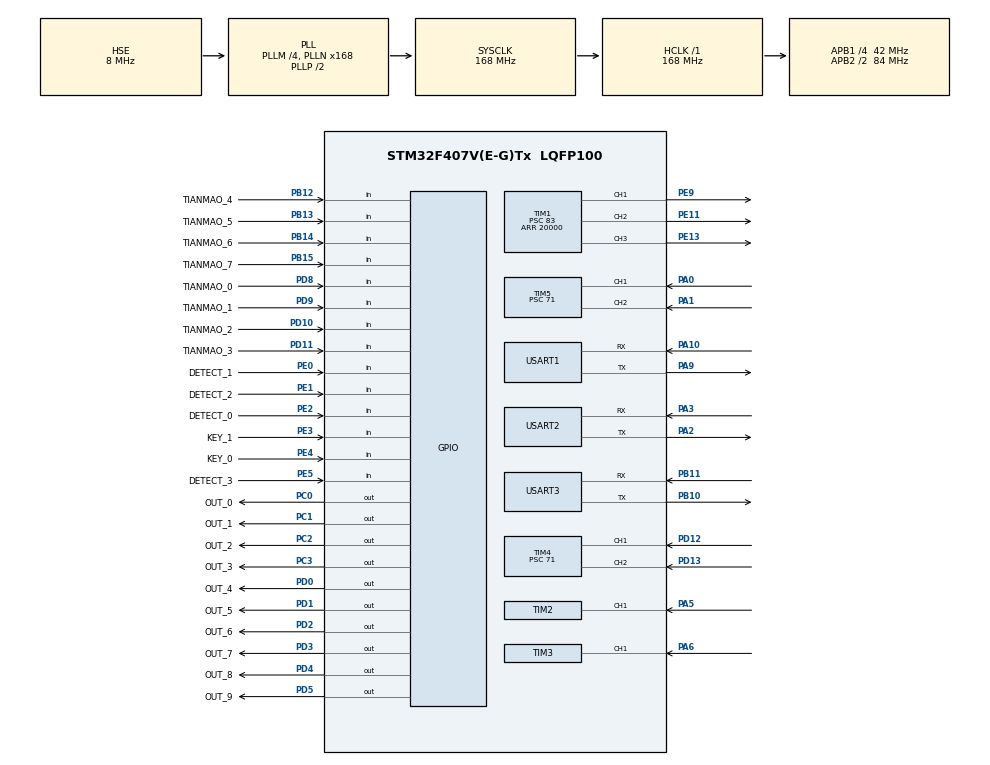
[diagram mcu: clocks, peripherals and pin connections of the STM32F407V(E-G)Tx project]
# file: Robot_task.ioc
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FREERTOS.INCLUDE_eTaskGetState=1
FREERTOS.INCLUDE_pcTaskGetTaskName=1
FREERTOS.INCLUDE_uxTaskGetStackHighWaterMark=1
FREERTOS.INCLUDE_uxTaskGetStackHighWaterMark2=1
FREERTOS.INCLUDE_vTaskCleanUpResources=1
FREERTOS.INCLUDE_vTaskDelayUntil=1
FREERTOS.INCLUDE_xQueueGetMutexHolder=1
FREERTOS.INCLUDE_xSemaphoreGetMutexHolder=1
FREERTOS.INCLUDE_xTaskAbortDelay=1
FREERTOS.INCLUDE_xTaskGetCurrentTaskHandle=1
FREERTOS.INCLUDE_xTaskGetHandle=1
FREERTOS.Tasks01=main_control,2,128,main_control_Task,Default,NULL,Dynamic,NULL,NULL;detect,1,128,detect_Task,Default,NULL,Dynamic,NULL,NULL;io_judge,0,128,io_Task,Default,NULL,Dynamic,NULL,NULL;wave_detect,0,128,wave_Task,Default,NULL,Dynamic,NULL,NULL;encoder,1,128,encoder_Task,Default,NULL,Dynamic,NULL,NULL
Mcu.Family=STM32F4
Mcu.Name=STM32F407V(E-G)Tx
Mcu.Package=LQFP100
NVIC.PriorityGroup=NVIC_PRIORITYGROUP_4
NVIC.TIM2_IRQn=true\:5\:0\:true\:false\:true\:true\:true\:true
NVIC.TIM3_IRQn=true\:5\:0\:true\:false\:true\:true\:true\:true
NVIC.TIM4_IRQn=true\:5\:0\:false\:false\:true\:true\:true\:true
NVIC.TIM5_IRQn=true\:5\:0\:false\:false\:true\:true\:true\:true
NVIC.USART1_IRQn=true\:5\:0\:false\:false\:true\:true\:true\:true
NVIC.USART2_IRQn=true\:5\:0\:false\:false\:true\:true\:true\:true
NVIC.USART3_IRQn=true\:5\:0\:false\:false\:true\:true\:true\:true
PA0-WKUP.Signal=S_TIM5_CH1
PA1.Signal=S_TIM5_CH2
PA10.Mode=Asynchronous
PA10.Signal=USART1_RX
PA2.Mode=Asynchronous
PA2.Signal=USART2_TX
PA3.Mode=Asynchronous
PA3.Signal=USART2_RX
PA5.Signal=S_TIM2_CH1_ETR
PA6.Signal=S_TIM3_CH1
PA9.Mode=Asynchronous
PA9.Signal=USART1_TX
PB10.Mode=Asynchronous
PB10.Signal=USART3_TX
PB11.Mode=Asynchronous
PB11.Signal=USART3_RX
PB12.GPIO_Label=TIANMAO_4
PB12.Signal=GPIO_Input
PB13.GPIO_Label=TIANMAO_5
PB13.Signal=GPIO_Input
PB14.GPIO_Label=TIANMAO_6
PB14.Signal=GPIO_Input
PB15.GPIO_Label=TIANMAO_7
PB15.Signal=GPIO_Input
PC0.GPIO_Label=OUT_0
PC0.Signal=GPIO_Output
PC1.GPIO_Label=OUT_1
PC1.Signal=GPIO_Output
PC2.GPIO_Label=OUT_2
PC2.Signal=GPIO_Output
PC3.GPIO_Label=OUT_3
PC3.Signal=GPIO_Output
PD0.GPIO_Label=OUT_4
PD0.Signal=GPIO_Output
PD1.GPIO_Label=OUT_5
PD1.Signal=GPIO_Output
PD10.GPIO_Label=TIANMAO_2
PD10.Signal=GPIO_Input
PD11.GPIO_Label=TIANMAO_3
PD11.Signal=GPIO_Input
PD12.Signal=S_TIM4_CH1
PD13.Signal=S_TIM4_CH2
PD2.GPIO_Label=OUT_6
PD2.Signal=GPIO_Output
PD3.GPIO_Label=OUT_7
PD3.Signal=GPIO_Output
PD4.GPIO_Label=OUT_8
PD4.Signal=GPIO_Output
PD5.GPIO_Label=OUT_9
PD5.Signal=GPIO_Output
PD8.GPIO_Label=TIANMAO_0
PD8.Signal=GPIO_Input
PD9.GPIO_Label=TIANMAO_1
PD9.Signal=GPIO_Input
PE0.GPIO_Label=DETECT_1
PE0.Signal=GPIO_Input
PE1.GPIO_Label=DETECT_2
PE1.Signal=GPIO_Input
PE11.Signal=S_TIM1_CH2
PE13.Signal=S_TIM1_CH3
PE2.GPIO_Label=DETECT_0
PE2.Signal=GPIO_Input
PE3.GPIO_Label=KEY_1
PE3.GPIO_PuPd=GPIO_PULLUP
PE3.Signal=GPIO_Input
PE4.GPIO_Label=KEY_0
PE4.GPIO_PuPd=GPIO_PULLUP
PE4.Signal=GPIO_Input
PE5.GPIO_Label=DETECT_3
PE5.Signal=GPIO_Input
PE9.Signal=S_TIM1_CH1
PH0-OSC_IN.Mode=HSE-External-Oscillator
PH0-OSC_IN.Signal=RCC_OSC_IN
PH1-OSC_OUT.Mode=HSE-External-Oscillator
PH1-OSC_OUT.Signal=RCC_OSC_OUT
ProjectManager.HeapSize=0x200
ProjectManager.StackSize=0x400
ProjectManager.TargetToolchain=MDK-ARM V5
RCC.48MHZClocksFreq_Value=84000000
RCC.AHBFreq_Value=168000000
RCC.APB1CLKDivider=RCC_HCLK_DIV4
RCC.APB1Freq_Value=42000000
RCC.APB1TimFreq_Value=84000000
RCC.APB2CLKDivider=RCC_HCLK_DIV2
RCC.APB2Freq_Value=84000000
RCC.APB2TimFreq_Value=168000000
RCC.CortexFreq_Value=168000000
RCC.HCLKFreq_Value=168000000
RCC.HSE_VALUE=8000000
RCC.HSI_VALUE=16000000
RCC.LSE_VALUE=32768
RCC.PLLM=4
RCC.PLLN=168
RCC.PLLSourceVirtual=RCC_PLLSOURCE_HSE
RCC.SYSCLKFreq_VALUE=168000000
RCC.SYSCLKSource=RCC_SYSCLKSOURCE_PLLCLK
RCC.VCOOutputFreq_Value=336000000
SH.S_TIM1_CH1.0=TIM1_CH1,PWM Generation1 CH1
SH.S_TIM1_CH2.0=TIM1_CH2,PWM Generation2 CH2
SH.S_TIM1_CH3.0=TIM1_CH3,PWM Generation3 CH3
SH.S_TIM2_CH1_ETR.0=TIM2_CH1,Input_Capture1_from_TI1
SH.S_TIM3_CH1.0=TIM3_CH1,Input_Capture1_from_TI1
SH.S_TIM4_CH1.0=TIM4_CH1,Encoder_Interface
SH.S_TIM4_CH2.0=TIM4_CH2,Encoder_Interface
SH.S_TIM5_CH1.0=TIM5_CH1,Encoder_Interface
SH.S_TIM5_CH2.0=TIM5_CH2,Encoder_Interface
TIM1.Channel-PWM\ Generation1\ CH1=TIM_CHANNEL_1
TIM1.Channel-PWM\ Generation2\ CH2=TIM_CHANNEL_2
TIM1.Channel-PWM\ Generation3\ CH3=TIM_CHANNEL_3
TIM1.Period=20000
TIM1.Prescaler=83
TIM2.Channel-Input_Capture1_from_TI1=TIM_CHANNEL_1
TIM2.Period=65535
TIM2.Prescaler=71
TIM3.Channel-Input_Capture1_from_TI1=TIM_CHANNEL_1
TIM3.Prescaler=7199
TIM4.Prescaler=71
TIM5.Period=65535
TIM5.Prescaler=71
TIM6.Prescaler=71
USART1.VirtualMode=VM_ASYNC
USART2.VirtualMode=VM_ASYNC
USART3.VirtualMode=VM_ASYNC
VP_FREERTOS_VS_CMSIS_V1.Mode=CMSIS_V1
VP_TIM6_VS_ClockSourceINT.Mode=Enable_Timer
board=custom

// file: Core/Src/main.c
/* USER CODE BEGIN Header */
/**
  ******************************************************************************
  * @file           : main.c
  * @brief          : Main program body
  ******************************************************************************
  * @attention
  *
  * <h2><center>&copy; Copyright (c) 2021 STMicroelectronics.
  * All rights reserved.</center></h2>
  *
  * This software component is licensed by ST under Ultimate Liberty license
  * SLA0044, the "License"; You may not use this file except in compliance with
  * the License. You may obtain a copy of the License at:
  *                             www.st.com/SLA0044
  *
  ******************************************************************************
  */
/* USER CODE END Header */
#include "main.h"
#include "cmsis_os.h"
#include "tim.h"
#include "usart.h"
#include "gpio.h"

/* USER CODE BEGIN Includes */
#include "motor.h"
#include "main_control.h"
#include "io_task.h"
/* USER CODE END Includes */

void SystemClock_Config(void);
void MX_FREERTOS_Init(void);

int main(void)
{

  /* MCU Configuration--------------------------------------------------------*/

  /* Reset of all peripherals, Initializes the Flash interface and the Systick. */
  HAL_Init();

  /* Configure the system clock */
  SystemClock_Config();

  /* Initialize all configured peripherals */
  MX_GPIO_Init();
  MX_TIM1_Init();
  MX_TIM2_Init();
  MX_TIM3_Init();
  MX_TIM4_Init();
  MX_TIM5_Init();
  MX_USART1_UART_Init();
  MX_USART2_UART_Init();
  MX_USART3_UART_Init();
  MX_TIM6_Init();
  /* USER CODE BEGIN 2 */
  motor_init();
	steer_control(0);
	while(KEY_0==1)
	{}
  /* USER CODE END 2 */

  /* Call init function for freertos objects (in freertos.c) */
  MX_FREERTOS_Init();
  /* Start scheduler */
  osKernelStart();

  /* We should never get here as control is now taken by the scheduler */
  /* Infinite loop */
  while (1)
  {

  }
}

void SystemClock_Config(void)
{
  RCC_OscInitTypeDef RCC_OscInitStruct = {0};
  RCC_ClkInitTypeDef RCC_ClkInitStruct = {0};

  /** Configure the main internal regulator output voltage
  */
  __HAL_RCC_PWR_CLK_ENABLE();
  __HAL_PWR_VOLTAGESCALING_CONFIG(PWR_REGULATOR_VOLTAGE_SCALE1);
  /** Initializes the RCC Oscillators according to the specified parameters
  * in the RCC_OscInitTypeDef structure.
  */
  RCC_OscInitStruct.OscillatorType = RCC_OSCILLATORTYPE_HSE;
  RCC_OscInitStruct.HSEState = RCC_HSE_ON;
  RCC_OscInitStruct.PLL.PLLState = RCC_PLL_ON;
  RCC_OscInitStruct.PLL.PLLSource = RCC_PLLSOURCE_HSE;
  RCC_OscInitStruct.PLL.PLLM = 4;
  RCC_OscInitStruct.PLL.PLLN = 168;
  RCC_OscInitStruct.PLL.PLLP = RCC_PLLP_DIV2;
  RCC_OscInitStruct.PLL.PLLQ = 4;
  if (HAL_RCC_OscConfig(&RCC_OscInitStruct) != HAL_OK)
  {
    Error_Handler();
  }
  /** Initializes the CPU, AHB and APB buses clocks
  */
  RCC_ClkInitStruct.ClockType = RCC_CLOCKTYPE_HCLK|RCC_CLOCKTYPE_SYSCLK
                              |RCC_CLOCKTYPE_PCLK1|RCC_CLOCKTYPE_PCLK2;
  RCC_ClkInitStruct.SYSCLKSource = RCC_SYSCLKSOURCE_PLLCLK;
  RCC_ClkInitStruct.AHBCLKDivider = RCC_SYSCLK_DIV1;
  RCC_ClkInitStruct.APB1CLKDivider = RCC_HCLK_DIV4;
  RCC_ClkInitStruct.APB2CLKDivider = RCC_HCLK_DIV2;

  if (HAL_RCC_ClockConfig(&RCC_ClkInitStruct, FLASH_LATENCY_5) != HAL_OK)
  {
    Error_Handler();
  }
}

void Error_Handler(void)
{
  __disable_irq();
  while (1)
  {
  }
}

/************************ (C) COPYRIGHT STMicroelectronics *****END OF FILE****/

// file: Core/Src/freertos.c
/* USER CODE BEGIN Header */
/**
  ******************************************************************************
  * File Name          : freertos.c
  * Description        : Code for freertos applications
  ******************************************************************************
  * @attention
  *
  * <h2><center>&copy; Copyright (c) 2021 STMicroelectronics.
  * All rights reserved.</center></h2>
  *
  * This software component is licensed by ST under Ultimate Liberty license
  * SLA0044, the "License"; You may not use this file except in compliance with
  * the License. You may obtain a copy of the License at:
  *                             www.st.com/SLA0044
  *
  ******************************************************************************
  */
/* USER CODE END Header */

#include "FreeRTOS.h"
#include "task.h"
#include "main.h"
#include "cmsis_os.h"

/* USER CODE BEGIN Includes */
#include "main_control.h"
#include "motor.h"
/* USER CODE END Includes */

osThreadId main_controlHandle;
osThreadId detectHandle;
osThreadId io_judgeHandle;
osThreadId wave_detectHandle;
osThreadId encoderHandle;

void main_control_Task(void const * argument);
void detect_Task(void const * argument);
void io_Task(void const * argument);
void wave_Task(void const * argument);
void encoder_Task(void const * argument);

void MX_FREERTOS_Init(void); /* (MISRA C 2004 rule 8.1) */

/* GetIdleTaskMemory prototype (linked to static allocation support) */
void vApplicationGetIdleTaskMemory( StaticTask_t **ppxIdleTaskTCBBuffer, StackType_t **ppxIdleTaskStackBuffer, uint32_t *pulIdleTaskStackSize );

/* USER CODE BEGIN GET_IDLE_TASK_MEMORY */
static StaticTask_t xIdleTaskTCBBuffer;
static StackType_t xIdleStack[configMINIMAL_STACK_SIZE];

void vApplicationGetIdleTaskMemory( StaticTask_t **ppxIdleTaskTCBBuffer, StackType_t **ppxIdleTaskStackBuffer, uint32_t *pulIdleTaskStackSize )
{
  *ppxIdleTaskTCBBuffer = &xIdleTaskTCBBuffer;
  *ppxIdleTaskStackBuffer = &xIdleStack[0];
  *pulIdleTaskStackSize = configMINIMAL_STACK_SIZE;
  /* place for user code */
}
/* USER CODE END GET_IDLE_TASK_MEMORY */

void MX_FREERTOS_Init(void) {

  /* Create the thread(s) */
  /* definition and creation of main_control */
  osThreadDef(main_control, main_control_Task, osPriorityHigh, 0, 128);
  main_controlHandle = osThreadCreate(osThread(main_control), NULL);

  /* definition and creation of detect */
  osThreadDef(detect, detect_Task, osPriorityAboveNormal, 0, 128);
  detectHandle = osThreadCreate(osThread(detect), NULL);

  /* definition and creation of io_judge */
  osThreadDef(io_judge, io_Task, osPriorityNormal, 0, 128);
  io_judgeHandle = osThreadCreate(osThread(io_judge), NULL);

  /* definition and creation of wave_detect */
  osThreadDef(wave_detect, wave_Task, osPriorityNormal, 0, 128);
  wave_detectHandle = osThreadCreate(osThread(wave_detect), NULL);

  /* definition and creation of encoder */
  osThreadDef(encoder, encoder_Task, osPriorityAboveNormal, 0, 128);
  encoderHandle = osThreadCreate(osThread(encoder), NULL);

}

//void main_control_Task(void const * argument)
//{
//  /* USER CODE BEGIN main_control_Task */
//////  /* Infinite loop */
//////  for(;;)
//////  {
//////    osDelay(1);
//////  }
//  /* USER CODE END main_control_Task */
//}

void detect_Task(void const * argument)
{
  for(;;)
  {
    osDelay(1);
  }
}

//void io_Task(void const * argument)
//{
//  /* USER CODE BEGIN io_Task */
//  /* Infinite loop */
//  for(;;)
//  {
//    osDelay(1);
//  }
//  /* USER CODE END io_Task */
//}

void wave_Task(void const * argument)
{
  for(;;)
  {
    osDelay(1);
  }
}

void encoder_Task(void const * argument)
{
  for(;;)
  {
    osDelay(1);
  }
}

/************************ (C) COPYRIGHT STMicroelectronics *****END OF FILE****/
